AUTOSAR XML (schema 00046)
package /VehicleProject
  system System
package /ECU
  ecu instance DUT: associated-com-i-pdu-group=[DUT_ominimal_system_Rx, DUT_ominimal_system_Tx]
    can communication controller CT_minimal_system
    can communication connector CN_minimal_system: comm-controller=CT_minimal_system
package /Cluster
  can cluster minimal_system: protocol-name=CAN
    can physical channel CHNL: comm-connectors=CN_minimal_system
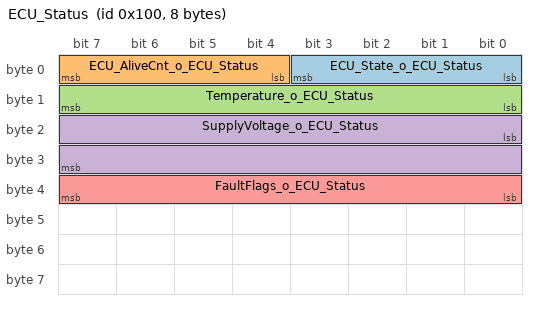
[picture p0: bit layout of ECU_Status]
      frame ECU_Status: id 0x100, from DUT, frame-length=8, can-addressing-mode=STANDARD
        pdu ECU_Status: length=8, unused-bit-pattern=0
          signal ECU_State_o_ECU_Status: start 0, 4 bit, little-endian, compu-method=CM_ECU_State, data-constr=DC_ECU_State, transfer-property=PENDING
          signal ECU_AliveCnt_o_ECU_Status: start 4, 4 bit, little-endian, compu-method=CM_ECU_AliveCnt, data-constr=DC_ECU_AliveCnt, transfer-property=PENDING
          signal Temperature_o_ECU_Status: start 8, 8 bit, little-endian, compu-method=CM_Temperature, data-constr=DC_Temperature, transfer-property=PENDING
          signal SupplyVoltage_o_ECU_Status: start 16, 16 bit, little-endian, compu-method=CM_SupplyVoltage, data-constr=DC_SupplyVoltage, transfer-property=PENDING
          signal FaultFlags_o_ECU_Status: start 32, 8 bit, little-endian, compu-method=CM_FaultFlags, data-constr=DC_FaultFlags, transfer-property=PENDING
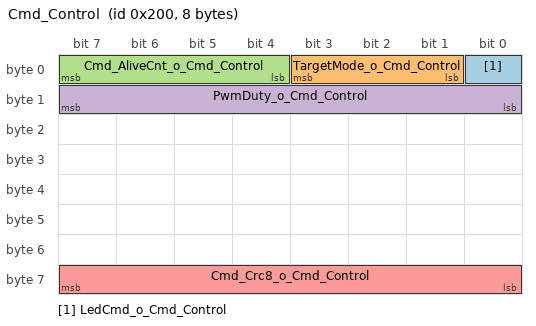
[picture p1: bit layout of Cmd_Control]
      frame Cmd_Control: id 0x200, to DUT, frame-length=8, can-addressing-mode=STANDARD
        pdu Cmd_Control: length=8, unused-bit-pattern=0
          signal LedCmd_o_Cmd_Control: start 0, 1 bit, little-endian, compu-method=CM_LedCmd, data-constr=DC_LedCmd, transfer-property=PENDING, to DUT
          signal TargetMode_o_Cmd_Control: start 1, 3 bit, little-endian, compu-method=CM_TargetMode, data-constr=DC_TargetMode, transfer-property=PENDING, to DUT
          signal Cmd_AliveCnt_o_Cmd_Control: start 4, 4 bit, little-endian, compu-method=CM_Cmd_AliveCnt, data-constr=DC_Cmd_AliveCnt, transfer-property=PENDING, to DUT
          signal PwmDuty_o_Cmd_Control: start 8, 8 bit, little-endian, compu-method=CM_PwmDuty, data-constr=DC_PwmDuty, transfer-property=PENDING, to DUT
          signal Cmd_Crc8_o_Cmd_Control: start 56, 8 bit, little-endian, compu-method=CM_Cmd_Crc8, data-constr=DC_Cmd_Crc8, transfer-property=PENDING, to DUT
      frame Fault_Event: id 0x300, from DUT, frame-length=2, can-addressing-mode=STANDARD
        pdu Fault_Event: length=2, unused-bit-pattern=0
          signal FaultCode_o_Fault_Event: start 0, 8 bit, little-endian, compu-method=CM_FaultCode, data-constr=DC_FaultCode, transfer-property=PENDING
          signal FaultActive_o_Fault_Event: start 8, 1 bit, little-endian, compu-method=CM_FaultActive, data-constr=DC_FaultActive, transfer-property=PENDING
package /IPDUGroup
  i signal i pdu group DUT_ominimal_system_Rx: communication-direction=IN, i-signal-i-pdus=Cmd_Control
  i signal i pdu group DUT_ominimal_system_Tx: communication-direction=OUT, i-signal-i-pdus=[ECU_Status, Fault_Event]
